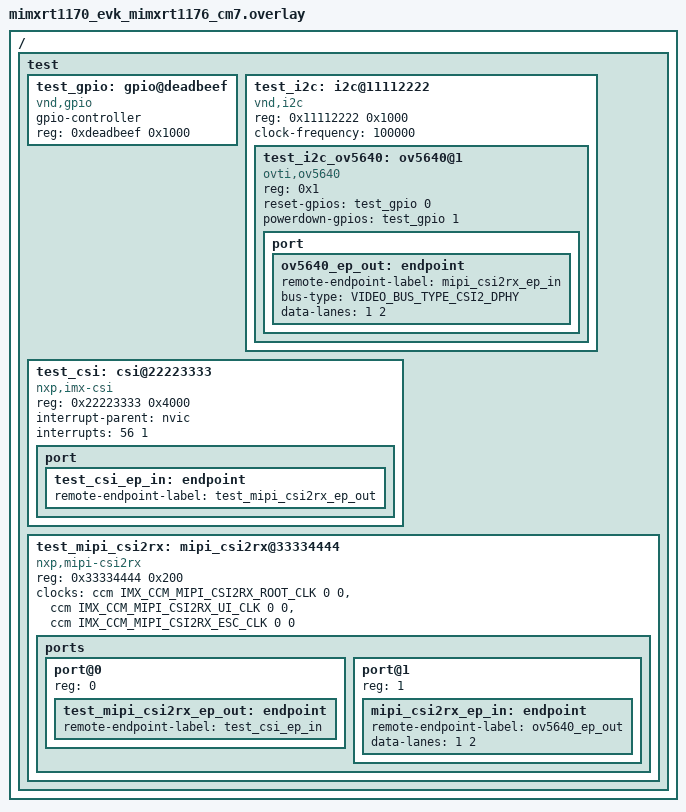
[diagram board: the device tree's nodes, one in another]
/*
 * Copyright 2024 NXP
 *
 * SPDX-License-Identifier: Apache-2.0
 *
 * Names in this file should be chosen in a way that won't conflict
 * with real-world devicetree nodes, to allow these tests to run on
 * (and be extended to test) real hardware.
 */

#include <zephyr/dt-bindings/video/video-interfaces.h>

/ {
	test {
		#address-cells = <1>;
		#size-cells = <1>;

		test_gpio: gpio@deadbeef {
			compatible = "vnd,gpio";
			gpio-controller;
			reg = <0xdeadbeef 0x1000>;
			#gpio-cells = <0x2>;
			status = "okay";
		};

		test_i2c: i2c@11112222 {
			#address-cells = <1>;
			#size-cells = <0>;
			compatible = "vnd,i2c";
			reg = <0x11112222 0x1000>;
			status = "okay";
			clock-frequency = <100000>;

			test_i2c_ov5640: ov5640@1 {
				compatible = "ovti,ov5640";
				reg = <0x1>;
				reset-gpios = <&test_gpio 0 0>;
				powerdown-gpios = <&test_gpio 1 0>;

				port {
					ov5640_ep_out: endpoint {
						remote-endpoint-label = "mipi_csi2rx_ep_in";
						bus-type = <VIDEO_BUS_TYPE_CSI2_DPHY>;
						data-lanes = <1 2>;
					};
				};
			};
		};

		test_csi: csi@22223333 {
			compatible = "nxp,imx-csi";
			reg = <0x22223333 0x4000>;
			status = "okay";
			interrupt-parent = <&nvic>;
			interrupts = <56 1>;

			port {
				test_csi_ep_in: endpoint {
					remote-endpoint-label = "test_mipi_csi2rx_ep_out";
				};
			};
		};

		test_mipi_csi2rx: mipi_csi2rx@33334444 {
			compatible = "nxp,mipi-csi2rx";
			reg = <0x33334444 0x200>;
			status = "okay";
			clocks = <&ccm IMX_CCM_MIPI_CSI2RX_ROOT_CLK 0 0>,
				 <&ccm IMX_CCM_MIPI_CSI2RX_UI_CLK 0 0>,
				 <&ccm IMX_CCM_MIPI_CSI2RX_ESC_CLK 0 0>;

			ports {
				#address-cells = <1>;
				#size-cells = <0>;

				port@0 {
					reg = <0>;
					test_mipi_csi2rx_ep_out: endpoint {
						remote-endpoint-label = "test_csi_ep_in";
					};
				};

				port@1 {
					reg = <1>;

					mipi_csi2rx_ep_in: endpoint {
						remote-endpoint-label = "ov5640_ep_out";
						data-lanes = <1 2>;
					};
				};
			};
		};
	};
};
